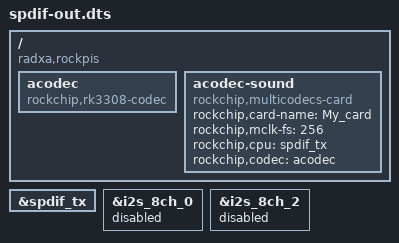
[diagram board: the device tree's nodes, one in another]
/dts-v1/;
/plugin/;

/ {
	compatible = "radxa,rockpis", "rockchip,rk3308";
	
	fragment@0 {
		target-path = "/";
		
		__overlay__ {
			acodec: acodec {
				#sound-dai-cells = <0>;
				compatible = "rockchip,rk3308-codec";
				status = "okay";
				};
			};
        };

	fragment@1 {
		target = <&spdif_tx>;
		
		__overlay__ {
				status = "okay";
			};
	};
	
        fragment@2 {
                target = <&i2s_8ch_0>;

                __overlay__ {
                        status = "disabled";
                };
        };
	
        fragment@3 {
                target = <&i2s_8ch_2>;

                __overlay__ {
                        status = "disabled";
                };
        };

	fragment@4 {
		target-path = "/";
		
		__overlay__ {
			acodec-sound {
				compatible = "rockchip,multicodecs-card";
				rockchip,card-name = "My_card";
				rockchip,mclk-fs = <256>;
				rockchip,cpu = <&spdif_tx>;
				rockchip,codec = <&acodec>;
				};
		    };
	  };
};
